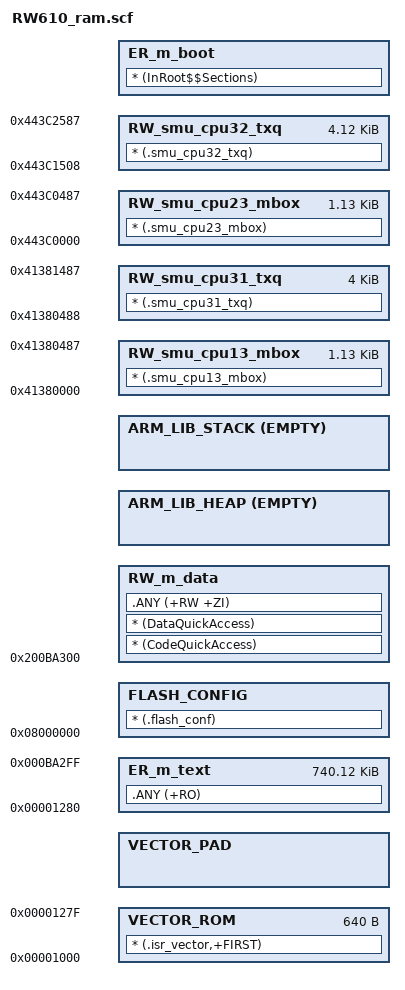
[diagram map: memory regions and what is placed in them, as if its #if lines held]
#!armclang --target=arm-arm-none-eabi -march=armv8-m.main -E -x c
/*
** ###################################################################
**     Processors:          RW612ETA2I
**                          RW612HNA2I
**                          RW612UKA2I
**
**     Compiler:            Keil ARM C/C++ Compiler
**     Reference manual:    RW61X User manual Rev. 0.95, June 2022
**     Version:             rev. 1.0, 2021-03-16
**     Build:               b231201
**
**     Abstract:
**         Linker file for the Keil ARM C/C++ Compiler
**
**     Copyright 2016 Freescale Semiconductor, Inc.
**     Copyright 2016-2023 NXP
**     SPDX-License-Identifier: BSD-3-Clause
**
**     http:                 www.nxp.com
**     mail:                 support@nxp.com
**
** ###################################################################
*/


/* Sizes */
#if (defined(__stack_size__))
  #define Stack_Size                   __stack_size__
#else
  #define Stack_Size                   0x0400
#endif

#if (defined(__heap_size__))
  #define Heap_Size                    __heap_size__
#else
  #define Heap_Size                    0x0400
#endif

#define  m_flash_start                 0x08000000

#define  m_boot_interrupts_start       0x08001000

#define  m_interrupts_start            0x00001000
#define  m_interrupts_size             0x00000280

#define  m_text_start                  0x00001280
#define  m_text_size                   0x000B9080

#define  m_data_start                  0x200BA300
#define  m_data_size                   0x00068D00
/* 0x2012_3000 - 0x2012_FFFF is reserved for BootROM usage */

#define  m_mbox1_start				   0x41380000
#define  m_mbox1_size				   0x00000488

#define  m_txq1_start                  0x41380488
#define  m_txq1_size                   0x00001000

#define  m_mbox2_start                 0x443C0000
#define  m_mbox2_size				   0x00000488

#define  m_txq23_start                 0x443C0488
#define  m_txq23_size				   0x00001080

#define  m_txq32_start                 0x443C1508
#define  m_txq32_size				   0x00001080

LR_m_flash_conf m_flash_start m_boot_interrupts_start-m_flash_start {
  FLASH_CONFIG +0 { ; load address = execution address
    * (.flash_conf)
  }
}

LR_m_interrupts m_boot_interrupts_start m_interrupts_size+m_text_size {
  VECTOR_ROM m_interrupts_start m_interrupts_size {
    * (.isr_vector,+FIRST)
  }
  VECTOR_PAD +0 FILL 0x0 m_text_start-ImageLimit(VECTOR_ROM) {
  }
  ER_m_text m_text_start m_text_size {
    .ANY (+RO)
  }

  RW_m_data m_data_start ALIGN 4 m_data_size-Stack_Size-Heap_Size { ; RW data
    * (CodeQuickAccess)
    * (DataQuickAccess)
    .ANY (+RW +ZI)
  }

  ARM_LIB_HEAP +0 EMPTY Heap_Size {    ; Heap region growing up
  }
  ARM_LIB_STACK m_data_start+m_data_size EMPTY -Stack_Size { ; Stack region growing down
  }
  
  RW_smu_cpu13_mbox m_mbox1_start ALIGN 4 m_mbox1_size { 
	* (.smu_cpu13_mbox)
  }
  
  RW_smu_cpu31_txq m_txq1_start ALIGN 4 m_txq1_size { 
	* (.smu_cpu31_txq)
  }
  
  RW_smu_cpu23_mbox m_mbox2_start ALIGN 4 m_mbox2_size { 
	* (.smu_cpu23_mbox)
  }
  
  RW_smu_cpu32_txq m_txq32_start ALIGN 4 m_txq32_size { 
	* (.smu_cpu32_txq)
  }
}

LR_m_boot +0 {
  ER_m_boot +0 { ; load address = execution address
    * (InRoot$$Sections)
  }
}
